# ATtiny841 register map
Vendor: Atmel
Registers are 8-bit, read-write, reset 0x0 unless marked. A register's access mark holds for its fields unless they carry their own. Offsets are from the block's base; [hi:lo] are bit positions; {n}, {i} and the like mark numbered series; <NAME> marks a mode.

## ADC — Analog-to-Digital Converter
Base 0x00000024
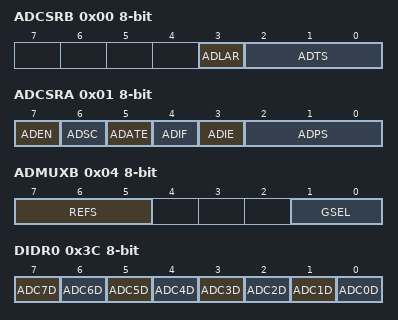
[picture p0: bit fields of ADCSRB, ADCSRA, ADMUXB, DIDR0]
0x00 ADCSRB — ADC Control and Status Register B
  [3] ADLAR — <TBD>
  [2:0] ADTS — ADC Auto Trigger Sources
    0=Free Running mode; 1=Analog Comparator 0; 2=External Interrupt Request 0; 3=Timer/Counter0 Compare Match A; 4=Timer/Counter0 Overflow; 5=Timer/Counter1 Compare Match A; 6=Timer/Counter1 Overflow; 7=Timer/Counter1 Capture Event
0x01 ADCSRA — The ADC Control and Status register
  [7] ADEN — ADC Enable
  [6] ADSC — ADC Start Conversion
  [5] ADATE — ADC Auto Trigger Enable
  [4] ADIF — ADC Interrupt Flag
  [3] ADIE — ADC Interrupt Enable
  [2:0] ADPS — ADC Prescaler Select Bits
    1=PRESCALER_2 (Prescaler Value 2); 2=PRESCALER_4 (Prescaler Value 4); 3=PRESCALER_8 (Prescaler Value 8); 4=PRESCALER_16 (Prescaler Value 16); 5=PRESCALER_32 (Prescaler Value 32); 6=PRESCALER_64 (Prescaler Value 64); 7=PRESCALER_128 (Prescaler Value 128)
0x02 ADC 16-bit (reset mask 0xFF) — ADC Data Register Bytes
0x04 ADMUXB — The ADC multiplexer Selection Register B
  [7:5] REFS — Reference Selection Bits
    0=VCC; 1=INTERNAL_1 (Internal 1.1V Voltage Reference with AREF disconnected); 2=INTERNAL_2 (Internal 2.2V Voltage Reference with AREF disconnected); 3=INTERNAL_4 (Internal 4.096V Voltage Reference with AREF disconnected); 4=AREF (AREF with internal reference off); 5=AREF_INTERNAL_1 (Internal 1.1V Voltage Reference with external capacitor at AREF pin); 6=AREF_INTERNAL_2 (Internal 2.2V Voltage Reference with external capacitor at AREF pin); 7=AREF_INTERNAL_4 (Internal 4.096V Voltage Reference with external capacitor at AREF pin)
  [1:0] GSEL — Gain Selection Bits
0x05 ADMUXA — The ADC multiplexer Selection Register A
  [5:0] MUX — Analog Channel and Gain Selection Bits
0x3C DIDR0 — Digital Input Disable Register 0
  [7] ADC7D — ADC7 Digital input Disable
  [6] ADC6D — ADC6 Digital input Disable
  [5] ADC5D — ADC5 Digital input Disable
  [4] ADC4D — ADC4/AIN11 Digital input Disable
  [3] ADC3D — ADC3/AIN10 Digital Input Disable
  [2] ADC2D — ADC2/AIN01 Digital input Disable
  [1] ADC1D — ADC1/AIN00 Digital input Disable
  [0] ADC0D — ADC0/AREF Digital input Disable
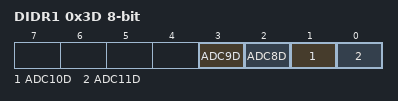
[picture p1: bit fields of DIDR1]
0x3D DIDR1 — Digital Input Disable Register 1
  [3] ADC9D — ADC9 Digital Input Disable
  [2] ADC8D — ADC8 Digital input Disable
  [1] ADC10D — ADC10 Digital input Disable
  [0] ADC11D — ADC11 Digital input Disable

## CPU — CPU Registers
Base 0x00000033
{0x0+i} GPIOR{i} (i=0..2) — General Purpose I/O Register {i}
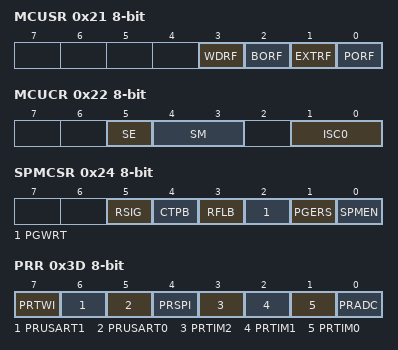
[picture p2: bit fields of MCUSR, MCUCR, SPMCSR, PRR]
0x21 MCUSR — MCU Status Register
  [3] WDRF — Watchdog Reset Flag
  [2] BORF — Brown-out Reset Flag
  [1] EXTRF — External Reset Flag
  [0] PORF — Power-on reset flag
0x22 MCUCR — MCU Control Register
  [5] SE — Sleep Enable
  [4:3] SM — Sleep Mode Select Bits
    0=IDLE; 1=ADC (ADC Noise Reduction (If Available)); 2=PDOWN (Power Down); 3=STDBY (Standby)
  [1:0] ISC0 — Interrupt Sense Control 0 bits
0x24 SPMCSR ro — Store Program Memory Control and Status Register
  [5] RSIG — Read Device Signature Imprint Table
  [4] CTPB — Clear Temporary Page Buffer
  [3] RFLB — Read Fuse and Lock Bits
  [2] PGWRT — Page Write
  [1] PGERS — Page Erase
  [0] SPMEN — Store program Memory Enable
0x3D PRR — Power Reduction Register
  [7] PRTWI — Power Reduction TWI
  [6] PRUSART1 — Power Reduction USART1
  [5] PRUSART0 — Power Reduction USART0
  [4] PRSPI — Power Reduction SPI
  [3] PRTIM2 — Power Reduction Timer/Counter2
  [2] PRTIM1 — Power Reduction Timer/Counter1
  [1] PRTIM0 — Power Reduction Timer/Counter0
  [0] PRADC — Power Reduction ADC
0x3E CCP — Configuration Change Protection
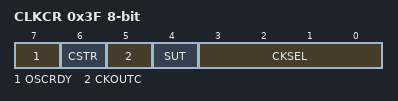
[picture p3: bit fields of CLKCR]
0x3F CLKCR — Clock Control Register
  [7] OSCRDY — Oscillator Ready
  [6] CSTR — Clock Switch Trigger
  [5] CKOUTC — Clock Output (Copy). Active low.
  [4] SUT — Start-up Time
  [3:0] CKSEL — Clock Select Bits
0x40 CLKPR — Clock Prescale Register
  [3:0] CLKPS — Clock Prescaler Select Bits
    0=1; 1=2; 2=4; 3=8; 4=16; 5=32; 6=64; 7=128; 8=256
0x41 OSCCAL0 — Oscillator Calibration Register 8MHz
0x42 OSCTCAL0A — Oscillator Temperature Calibration Register A
0x43 OSCTCAL0B — Oscillator Temperature Calibration Register B
0x44 OSCCAL1 — Oscillator Calibration Register 32kHz
